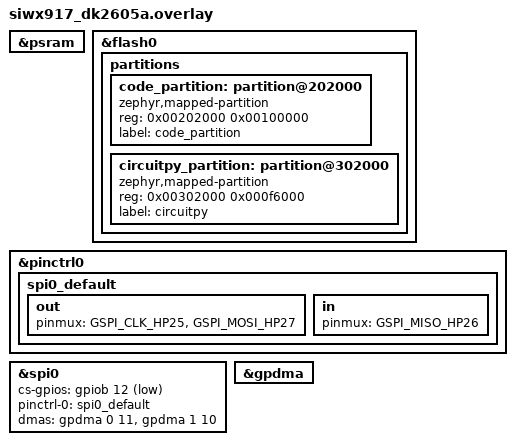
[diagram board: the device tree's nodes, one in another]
// Replaces the port's app.overlay, which cannot be used here: it does
// `&zephyr_udc0 { ... }` to add the CDC-ACM console, and the SiWG917 has no USB
// device controller. The CircuitPython console falls back to the Zephyr console
// on &ulpuart, reaching the host over the on-board J-Link VCOM.

// CIRCUITPY filesystem.
//
// supervisor/flash.c looks for a partition node labeled `circuitpy_partition`
// (#define CIRCUITPY_PARTITION circuitpy_partition). Without it the port falls
// back to scanning for a flash device not covered by any partition, finds none
// on this board, prints "no flash found for filesystem" and boots into safe
// mode with "CIRCUITPY drive could not be found or created".
//
// The whole 8 MB is already partitioned by siwg917m111mgtba.dtsi, so there is
// no unallocated space to claim:
//   0x000000..0x011000  mbr_nwp                        (do not touch)
//   0x011000..0x1f0000  code_nwp  - NWP firmware       (do not touch)
//   0x1f0000..0x202000  mbr + hdr                      (do not touch)
//   0x202000..0x3f8000  code_partition - our M4 app
//   0x3f8000..0x400000  storage   - only 32 KB, unusable as CIRCUITPY
//   0x400000..0x800000  ota_swap_partition
//   0x7cf000..0x800000  storage_nwp, storage_shared, backup_bootloader
//
// Placing CIRCUITPY in the upper region (0x400000..0x7cf000, inside ota_swap)
// opens and reads fine but every write fails:
//
//   flash write failed: -5      (-EIO)
//     address 0 length 512
//
// In common-flash mode the M4 cannot write flash itself; the driver calls
// sl_si91x_command_to_write_common_flash() to have the NWP do it, and the NWP
// refuses writes in the OTA-swap/NWP-owned upper area.
//
// So carve CIRCUITPY out of the M4's own code_partition instead, which is
// definitely writable - it is where our firmware is flashed. code_partition is
// shrunk from 2008K to 1M (the image currently uses ~703K, so there is room;
// if it ever overflows the build fails loudly at link time rather than
// silently corrupting the filesystem).
//
//   0x202000 + 1M      code_partition   -> ends 0x302000
//   0x302000 + 984K    circuitpy        -> ends 0x3f8000
//   0x3f8000 + 32K     storage (unchanged)
// The 8 MB PSRAM at 0xa000000 works as memory: sparse writes across a 64 KB
// buffer verify correctly and a 64 KB allocation succeeds. But using it as the
// Python heap corrupts objects under sustained allocation, and the failure is
// not about large buffers - a plain `for i in range(200000): s = s + i` with no
// buffer at all hangs the board. Symptoms are corrupted objects: an int that
// became a function, a bytearray with a wrong length, and an MPU fault calling
// a garbage pointer read from PSRAM:
//
//   ***** MPU FAULT *****  Instruction Access Violation
//   r0/a1: 0x0a0012c0  r12/ip: 0x0a0031ac   <- PSRAM pointers
//   PC:    0x410e29c8                       <- called through r3, garbage
//
// Not a timing problem: identical at fast-freq 144 MHz and 33 MHz. Not the
// NWP-reserved/DMA pools either; excluding those (supervisor/port.c minimum
// region size) did not help.
//
// ROOT CAUSE FOUND 2026-08-01, and the node is enabled again.
//
// The SoC has a 16 KB data cache dedicated to PSRAM (family RM rev 1.2 section
// 5.4.5) at 0x44040000, on the QSPI2 path. The bootloader leaves it enabled and
// half-configured, and nothing in this build maintains it - see the long
// comment in supervisor/port.c, which disables it in port_heap_init() before
// any TLSF pool exists.
//
// Note what did NOT work, so it is not retried: setting ATTR_MPU_RAM_NOCACHE on
// this node changes nothing. That is an MPU attribute governing the Cortex-M
// architectural cache, and CPU_HAS_DCACHE is never selected, so there is
// nothing there for it to govern. The cache that matters is a separate
// peripheral and an MPU attribute does not reach it.
&psram {
	status = "okay";
};

&flash0 {
	partitions {
		code_partition: partition@202000 {
			compatible = "zephyr,mapped-partition";
			reg = <0x00202000 0x00100000>;
			label = "code_partition";
		};

		circuitpy_partition: partition@302000 {
			compatible = "zephyr,mapped-partition";
			reg = <0x00302000 0x000f6000>;
			label = "circuitpy";
		};
	};
};

// --- SPI (GSPI) --------------------------------------------------------------
// Issue mikeysklar/circuitpython#3. The board .dts leaves spi0 disabled and carries a bare
// `/* TODO: Add ICMCM-40627 with SSI */` comment; nothing wires the bus.
//
// Pin assignment is NOT guessed. Upstream Zephyr already ships a verified
// mapping for this exact board in
// zephyr/tests/drivers/spi/spi_loopback/boards/siwx917_dk2605a.overlay
// (Silicon Laboratories Inc., 2025), which routes GSPI to the breakout pads:
//
//   CLK  -> GSPI_CLK_HP25    (breakout PAD 3)
//   MOSI -> GSPI_MOSI_HP27   (breakout PAD 5)
//   MISO -> GSPI_MISO_HP26   (breakout PAD 7)
//   CS   -> gpiob 12, active low
//
// Note the SoC dtsi has exactly ONE SPI controller node, spi0, and it is
// `compatible = "silabs,gspi"`. There is no `ssi` node in
// dts/arm/silabs/siwg917.dtsi at all, so the board comment's "with SSI" is not
// reachable from devicetree today: SSI and GSPI are separate peripherals in the
// WiSeConnect HAL (peripherals-ssi vs peripherals-gspi) and Zephyr ships only a
// GSPI controller driver (drivers/spi/spi_silabs_siwx91x_gspi.c). SSI pinmux
// macros exist in siwx91x-pinctrl.h but have no controller behind them.
//
// Per UG581 §3.4.3 Fig 3.6 the on-board ICM-40627 IMU is on the ULP SPI via
// ULP GPIO pins (ULP_GPIO_8/1/2/10), a third bus distinct from both GSPI and
// SSI — see issue mikeysklar/circuitpython#4. This GSPI bus serves the breakout pads only.
//
// cptools/compat2driver.py already maps "silabs_gspi" -> "spi", so enabling the
// node is sufficient for zephyr2cp.py to emit board.SPI / busio.SPI.
&pinctrl0 {
	spi0_default: spi0_default {
		out {
			pinmux = <GSPI_CLK_HP25>, <GSPI_MOSI_HP27>;
		};

		in {
			pinmux = <GSPI_MISO_HP26>;
		};
	};
};

&spi0 {
	status = "okay";
	cs-gpios = <&gpiob 12 GPIO_ACTIVE_LOW>;
	pinctrl-0 = <&spi0_default>;
	pinctrl-names = "default";

	dmas = <&gpdma 0 11>, <&gpdma 1 10>;
	dma-names = "tx", "rx";
};

&gpdma {
	status = "okay";
};
